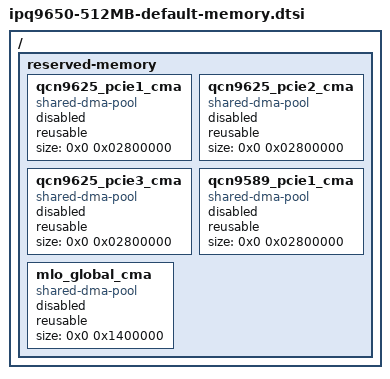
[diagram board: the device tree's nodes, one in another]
// SPDX-License-Identifier: (GPL-2.0+ OR BSD-3-Clause)
/*
 * IPQ9650 512MB Memory device tree source
 *
 * Copyright (c) Qualcomm Technologies, Inc. and/or its subsidiaries.
 */

/ {
	/*                    512MB Profile
	 * +==========+==============+========================+
	 * |         |              |                         |
	 * |  Region | Start Offset |          Size           |
	 * |         |              |                         |
	 * +---------+--------------+-------------------------+
	 * |         |              |                         |
	 * | QCN9625 |    DYNAMIC   |          40MB           |
	 * | PCIe1   |              |                         |
	 * |         |              |                         |
	 * +---------+--------------+-------------------------+
	 * |         |              |                         |
	 * | QCN9625 |    DYNAMIC   |          40MB           |
	 * | PCIe2   |              |                         |
	 * |         |              |                         |
	 * +---------+--------------+-------------------------+
	 * |         |              |                         |
	 * | QCN9625 |    DYNAMIC   |          40MB           |
	 * | PCIe3   |              |                         |
	 * |         |              |                         |
	 * +---------+--------------+-------------------------+
	 * |         |              |                         |
	 * | QCN9589 |    DYNAMIC   |          40MB           |
	 * | PCIe1   |              |                         |
	 * |         |              |                         |
	 * +---------+--------------+-------------------------+
	 * |         |              |                         |
	 * |  MLO    |    DYNAMIC   |          20MB           |
	 * |         |              |                         |
	 * +==================================================+
	 * |                                                  |
	 * |                                                  |
	 * |                                                  |
	 * |             Rest of memory for Linux             |
	 * |                                                  |
	 * |                                                  |
	 * |                                                  |
	 * +==================================================+
	 */

	reserved-memory {
		#address-cells = <2>;
		#size-cells = <2>;
		ranges;

		qcn9625_pcie1_cma: qcn9625_pcie1_cma {
			compatible = "shared-dma-pool";
			reusable;
			size = <0x0 0x02800000>;
			status = "disabled";
		};

		qcn9625_pcie2_cma: qcn9625_pcie2_cma {
			compatible = "shared-dma-pool";
			reusable;
			size = <0x0 0x02800000>;
			status = "disabled";
		};

		qcn9625_pcie3_cma: qcn9625_pcie3_cma {
			compatible = "shared-dma-pool";
			reusable;
			size = <0x0 0x02800000>;
			status = "disabled";
		};

		qcn9589_pcie1_cma: qcn9589_pcie1_cma {
			compatible = "shared-dma-pool";
			reusable;
			size = <0x0 0x02800000>;
			status = "disabled";
		};

		mlo_global_cma: mlo_global_cma {
			compatible = "shared-dma-pool";
			reusable;
			size = <0x0 0x1400000>;
			status = "disabled";
		};
	};
};
